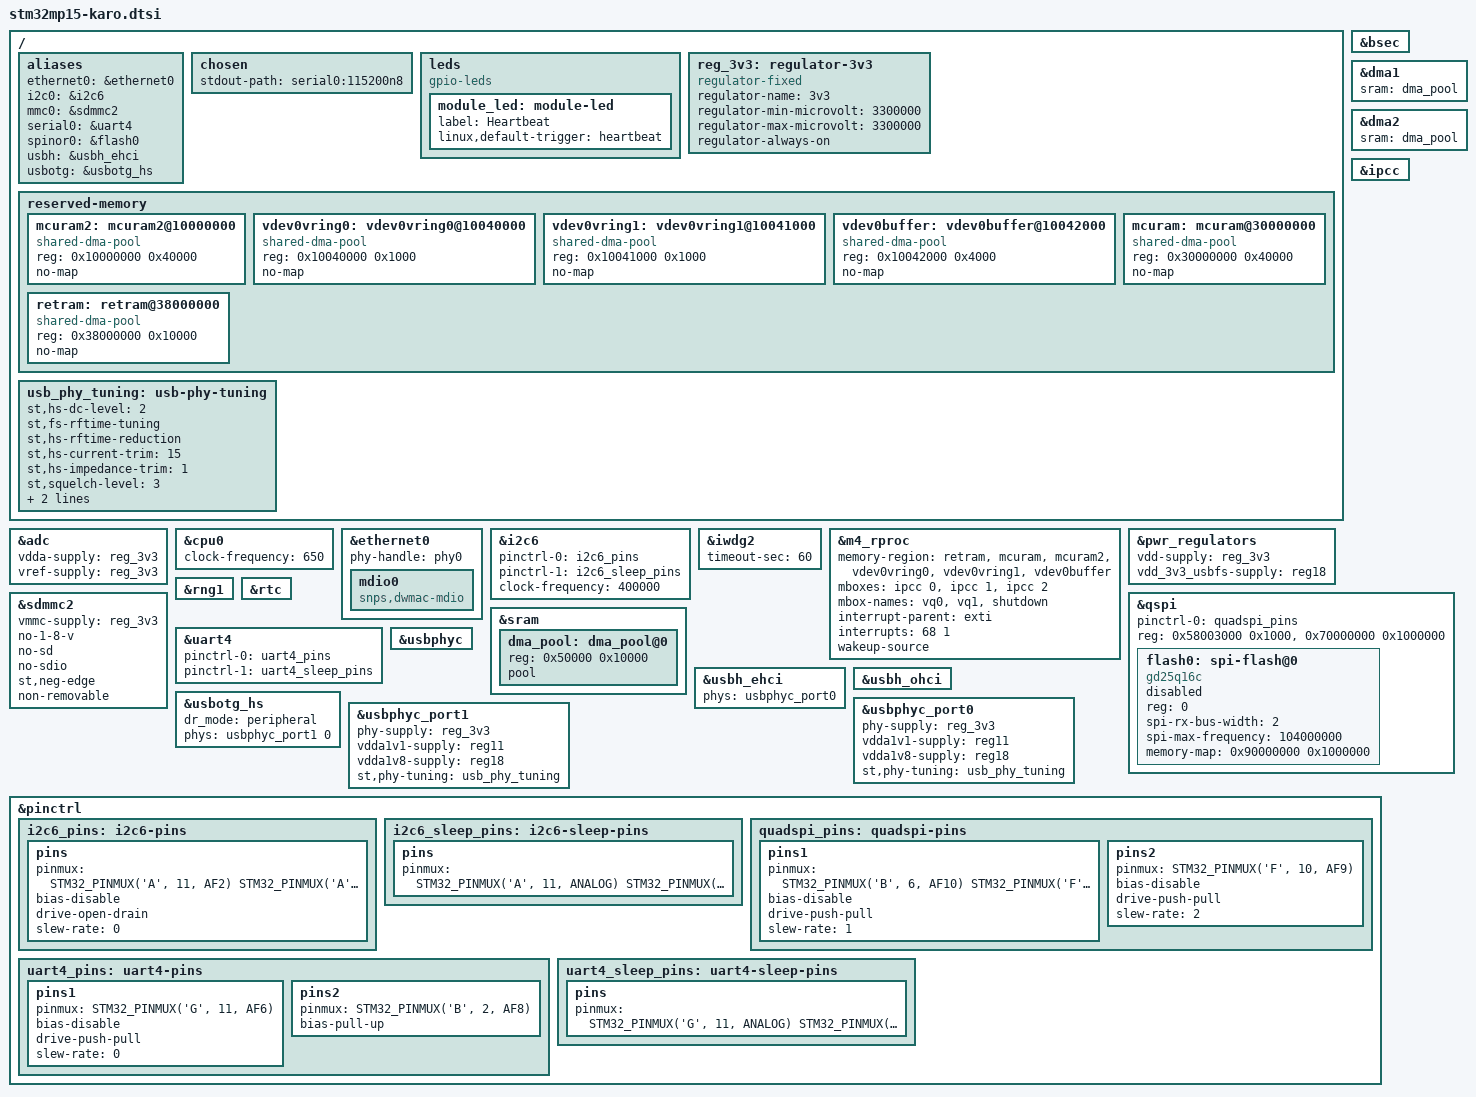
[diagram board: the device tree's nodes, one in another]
// SPDX-License-Identifier: (GPL-2.0 OR BSD-3-Clause)
/*
 * Copyright (C) 2020 Lothar Waßmann <LW@KARO-electronics.de>
 */

#include <dt-bindings/clock/stm32mp1-clks.h>
#include <dt-bindings/gpio/gpio.h>
#include <dt-bindings/pwm/pwm.h>

/ {
	aliases {
		ethernet0 = &ethernet0;
		i2c0 = &i2c6;
		mmc0 = &sdmmc2;
		serial0 = &uart4;
		spinor0 = &flash0;
		usbh = &usbh_ehci;
		usbotg = &usbotg_hs;
	};

	chosen {
		stdout-path = "serial0:115200n8";
	};

	leds {
		compatible = "gpio-leds";

		module_led: module-led {
			label = "Heartbeat";
			linux,default-trigger = "heartbeat";
		};
	};

	reg_3v3: regulator-3v3 {
		compatible = "regulator-fixed";
		regulator-name = "3v3";
		regulator-min-microvolt = <3300000>;
		regulator-max-microvolt = <3300000>;
		regulator-always-on;
	};

	reserved-memory {
		#address-cells = <1>;
		#size-cells = <1>;
		ranges;

		mcuram2: mcuram2@10000000 {
			compatible = "shared-dma-pool";
			reg = <0x10000000 0x40000>;
			no-map;
		};

		vdev0vring0: vdev0vring0@10040000 {
			compatible = "shared-dma-pool";
			reg = <0x10040000 0x1000>;
			no-map;
		};

		vdev0vring1: vdev0vring1@10041000 {
			compatible = "shared-dma-pool";
			reg = <0x10041000 0x1000>;
			no-map;
		};

		vdev0buffer: vdev0buffer@10042000 {
			compatible = "shared-dma-pool";
			reg = <0x10042000 0x4000>;
			no-map;
		};

		mcuram: mcuram@30000000 {
			compatible = "shared-dma-pool";
			reg = <0x30000000 0x40000>;
			no-map;
		};

		retram: retram@38000000 {
			compatible = "shared-dma-pool";
			reg = <0x38000000 0x10000>;
			no-map;
		};
	};

	usb_phy_tuning: usb-phy-tuning {
		st,hs-dc-level = <2>;
		st,fs-rftime-tuning;
		st,hs-rftime-reduction;
		st,hs-current-trim = <15>;
		st,hs-impedance-trim = <1>;
		st,squelch-level = <3>;
		st,hs-rx-offset = <2>;
		st,no-lsfs-sc;
	};
};

&adc {
	vdda-supply = <&reg_3v3>;
	vref-supply = <&reg_3v3>;
};

&bsec {
	status = "okay";
};

&cpu0 {
	clock-frequency = <650>;
};

&dma1 {
	sram = <&dma_pool>;
};

&dma2 {
	sram = <&dma_pool>;
};

&ethernet0 {
	pinctrl-names = "default", "sleep";
	phy-handle = <&phy0>;
	status = "okay";

	mdio0: mdio0 {
		#address-cells = <1>;
		#size-cells = <0>;
		compatible = "snps,dwmac-mdio";
	};
};

&i2c6 {
	pinctrl-names = "default", "sleep";
	pinctrl-0 = <&i2c6_pins>;
	pinctrl-1 = <&i2c6_sleep_pins>;
	clock-frequency = <400000>;
	status = "okay";
};

&ipcc {
	status = "okay";
};

&iwdg2 {
	timeout-sec = <60>;
	status = "okay";
};

&m4_rproc {
	memory-region = <&retram>, <&mcuram>, <&mcuram2>, <&vdev0vring0>,
			<&vdev0vring1>, <&vdev0buffer>;
	mboxes = <&ipcc 0>, <&ipcc 1>, <&ipcc 2>;
	mbox-names = "vq0", "vq1", "shutdown";
	interrupt-parent = <&exti>;
	interrupts = <68 1>;
	wakeup-source;
	status = "okay";
};

&pwr_regulators {
	vdd-supply = <&reg_3v3>;
	vdd_3v3_usbfs-supply = <&reg18>;
};

&qspi {
	pinctrl-names = "default";
	pinctrl-0 = <&quadspi_pins>;
	reg = <0x58003000 0x1000>, <0x70000000 0x1000000>;
	status = "okay";

	flash0: spi-flash@0 {
		#address-cells = <1>;
		#size-cells = <1>;
		compatible = "gd25q16c", "spi-flash";
		reg = <0>;
		spi-rx-bus-width = <2>;
		spi-max-frequency = <104000000>;
		memory-map = <0x90000000 0x1000000>;
		status = "disabled";
	};
};

&rng1 {
	status = "okay";
};

&rtc {
	status = "okay";
};

&sdmmc2 {
	/* eMMC */
	pinctrl-names = "default", "opendrain", "sleep";
	vmmc-supply = <&reg_3v3>;
	no-1-8-v;
	no-sd;
	no-sdio;
	st,neg-edge;
	non-removable;
	status = "okay";
};

&sram {
	dma_pool: dma_pool@0 {
		reg = <0x50000 0x10000>;
		pool;
	};
};

&uart4 {
	pinctrl-names = "default", "sleep";
	pinctrl-0 = <&uart4_pins>;
	pinctrl-1 = <&uart4_sleep_pins>;
	/delete-property/ dma-names;
	/delete-property/ dmas;
	status = "okay";
};

&usbh_ehci {
	phys = <&usbphyc_port0>;
	status = "okay";
};

&usbh_ohci {
	status = "okay";
};

&usbotg_hs {
	dr_mode = "peripheral";
	phys = <&usbphyc_port1 0>;
	phy-names = "usb2-phy";
	status = "okay";
};

&usbphyc {
	status = "okay";
};

&usbphyc_port0 {
	phy-supply = <&reg_3v3>;
	vdda1v1-supply = <&reg11>;
	vdda1v8-supply = <&reg18>;
	st,phy-tuning = <&usb_phy_tuning>;
	status = "okay";
};

&usbphyc_port1 {
	phy-supply = <&reg_3v3>;
	vdda1v1-supply = <&reg11>;
	vdda1v8-supply = <&reg18>;
	st,phy-tuning = <&usb_phy_tuning>;
	status = "okay";
};

&pinctrl {
	i2c6_pins: i2c6-pins {
		pins {
			pinmux = <
				  STM32_PINMUX('A', 11, AF2) /* I2C6_SCL */
				  STM32_PINMUX('A', 12, AF2) /* I2C6_SDA */
			>;
			bias-disable;
			drive-open-drain;
			slew-rate = <0>;
		};
	};

	i2c6_sleep_pins: i2c6-sleep-pins {
		pins {
			pinmux = <
				  STM32_PINMUX('A', 11, ANALOG) /* I2C6_SCL */
				  STM32_PINMUX('A', 12, ANALOG) /* I2C6_SDA */
			>;
		};
	};

	quadspi_pins: quadspi-pins {
		pins1 {
			pinmux = <
				  STM32_PINMUX('B', 6, AF10)	/* QUADSPI_BK1_NCS */
				  STM32_PINMUX('F', 9, AF10)	/* QUADSPI_BK1_IO1 */
				  STM32_PINMUX('F', 8, AF10)	/* QUADSPI_BK1_IO0 */
			>;
			bias-disable;
			drive-push-pull;
			slew-rate = <1>;
		};

		pins2 {
			pinmux = <STM32_PINMUX('F', 10, AF9)>; /* QUADSPI_CLK */
			bias-disable;
			drive-push-pull;
			slew-rate = <2>;
		};
	};

	uart4_pins: uart4-pins {
		pins1 {
			pinmux = <STM32_PINMUX('G', 11, AF6)>; /* UART4_TX */
			bias-disable;
			drive-push-pull;
			slew-rate = <0>;
		};

		pins2 {
			pinmux = <STM32_PINMUX('B', 2, AF8)>; /* UART4_RX */
			bias-pull-up;
		};
	};

	uart4_sleep_pins: uart4-sleep-pins {
		pins {
			pinmux = <
				  STM32_PINMUX('G', 11, ANALOG) /* UART4_TX */
				  STM32_PINMUX('B', 2, ANALOG) /* UART4_RX */
			>;
		};
	};
};
